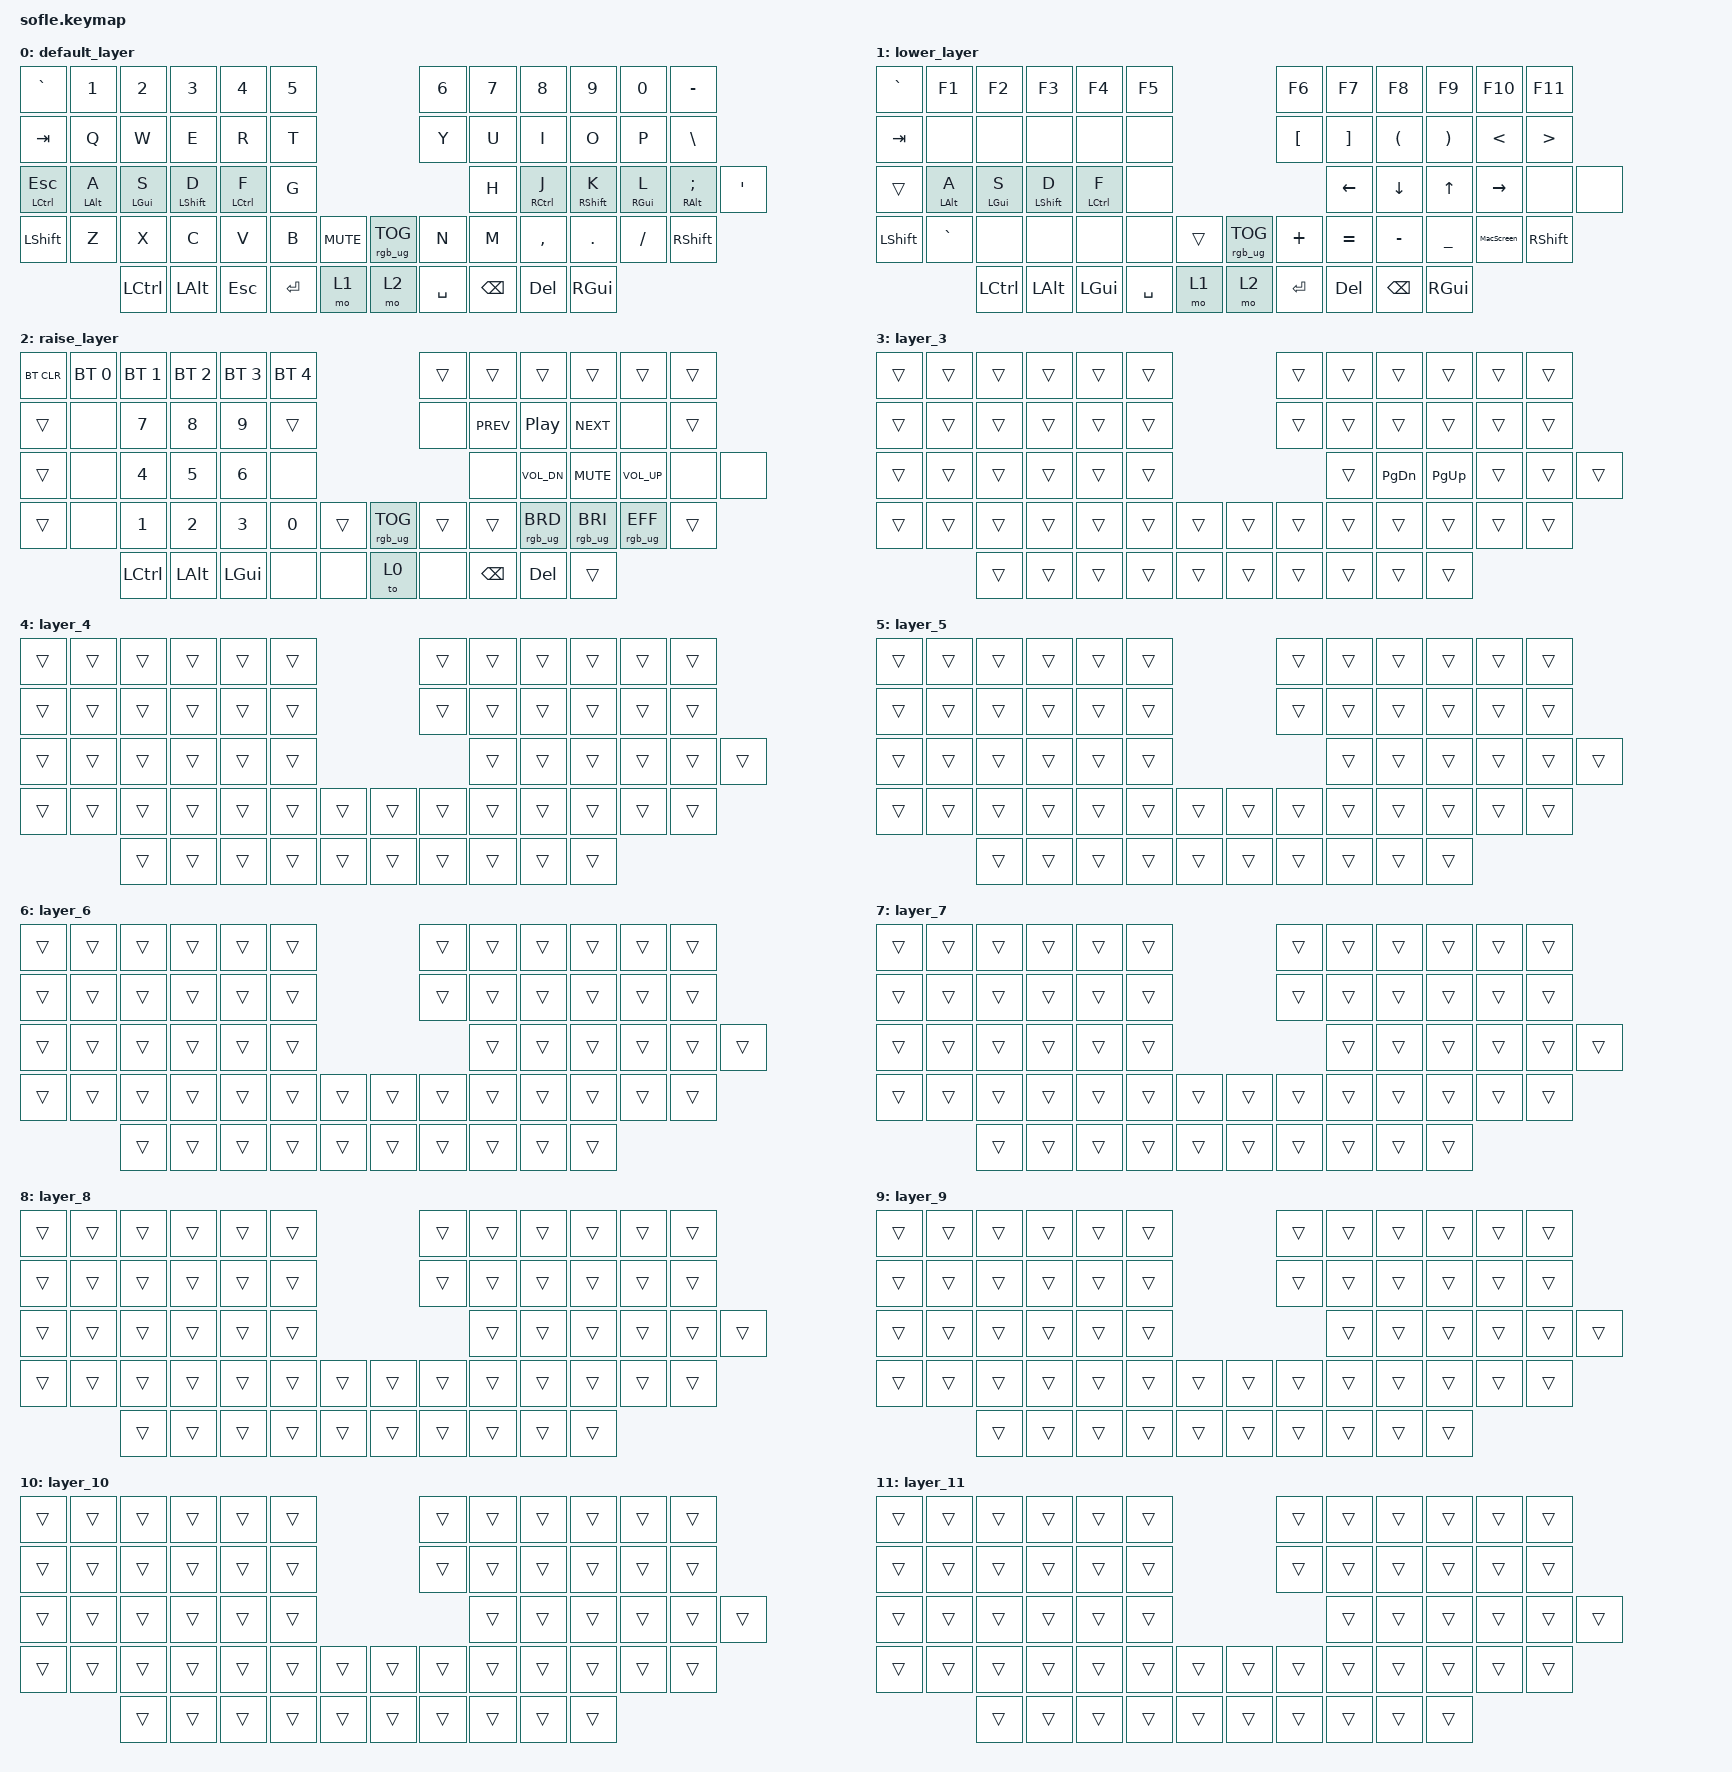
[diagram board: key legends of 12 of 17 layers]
/*
 * Copyright (c) 2020 The ZMK Contributors
 *
 * SPDX-License-Identifier: MIT
 */

#include <dt-bindings/led/led.h>
#include <behaviors.dtsi>
#include <dt-bindings/zmk/bt.h>
#include <dt-bindings/zmk/keys.h>
#include <dt-bindings/zmk/rgb.h>

&pinctrl {
    spi3_default: spi3_default {
        group1 { psels = <NRF_PSEL(SPIM_MOSI, 0, 8)>; };
    };

    spi3_sleep: spi3_sleep {
        group1 {
            psels = <NRF_PSEL(SPIM_MOSI, 0, 8)>;
            low-power-enable;
        };
    };
};

&spi3 {
    compatible = "nordic,nrf-spim";
    status = "okay";
    pinctrl-0 = <&spi3_default>;
    pinctrl-1 = <&spi3_sleep>;
    pinctrl-names = "default", "sleep";

    led_strip: ws2812@0 {
        compatible = "worldsemi,ws2812-spi";
        label = "WS2812";

        /* SPI */
        reg = <0>;
        spi-max-frequency = <4000000>;

        /* WS2812 */
        chain-length = <30>;
        spi-one-frame = <0x70>;
        spi-zero-frame = <0x40>;
        color-mapping = <LED_COLOR_ID_GREEN LED_COLOR_ID_RED LED_COLOR_ID_BLUE>;
    };
};

/ {
    chosen { zmk,underglow = &led_strip; };
};

/ {
    macros {
        MacScreen: MacScreen {
            compatible = "zmk,behavior-macro";
            #binding-cells = <0>;
            bindings = <&kp LSHFT &kp LCTRL &kp LGUI &kp KP_NUMBER_4>;
            label = "MACSCREEN";
        };
    };

    behaviors {
        // Caps key -> tap: ESC, hold: LCTRL
        escctrl: escape_control {
            compatible = "zmk,behavior-hold-tap";
            #binding-cells = <2>;
            tapping-term-ms = <200>;
            quick-tap-ms = <125>;
            flavor = "tap-preferred";
            bindings = <&kp>, <&kp>;
        };

        // Homerow mods - left hand
        // hold-trigger positions = all right hand keys so holds only fire toward opposite hand
        hml: homerow_mods_left {
            compatible = "zmk,behavior-hold-tap";
            #binding-cells = <2>;
            tapping-term-ms = <280>;
            quick-tap-ms = <175>;
            require-prior-idle-ms = <150>;
            flavor = "balanced";
            hold-trigger-key-positions = <
                6  7  8  9  10 11
                18 19 20 21 22 23
                30 31 32 33 34 35
                39 40 41 42 43 44 45 46 47 48 49 50 51
            >;
            hold-trigger-on-release;
            bindings = <&kp>, <&kp>;
        };

        // Homerow mods - right hand
        hmr: homerow_mods_right {
            compatible = "zmk,behavior-hold-tap";
            #binding-cells = <2>;
            tapping-term-ms = <280>;
            quick-tap-ms = <175>;
            require-prior-idle-ms = <150>;
            flavor = "balanced";
            hold-trigger-key-positions = <
                0  1  2  3  4  5
                12 13 14 15 16 17
                24 25 26 27 28 29
                36 37 38 39 40 41 42 43 44 45 46 47 48
            >;
            hold-trigger-on-release;
            bindings = <&kp>, <&kp>;
        };
    };

    keymap {
        compatible = "zmk,keymap";

        default_layer {
            // ---------------------------------------------------------------------------------------------------------------
            // |  `    |  1  |  2  |  3   |  4   |  5   |                         |  6   |  7    |  8    |  9   |   0   |  -   |
            // |  TAB  |  Q  |  W  |  E   |  R   |  T   |                         |  Y   |  U    |  I    |  O   |   P   |  \   |
            // |ESC/CTL|  A  |S/GUI|D/SFT |F/CTL |  G   |                         |  H   |J/CTL  |K/SFT  |L/GUI |;/RALT |  '   |
            // | SHIFT |  Z  |  X  |  C   |  V   |  B   |  MUTE  |      | RGB_TOG |  N   |  M    |  ,    |  .   |   /   | SHIFT|
            //               | CTRL| ALT  | GUI  | LOWER| SPACE  |      | ENTER   | RAISE| BSPC  | DEL   | GUI  |

            bindings = <
&kp GRAVE          &kp N1  &kp N2         &kp N3        &kp N4        &kp N5                                      &kp N6  &kp N7         &kp N8     &kp N9    &kp N0    &kp MINUS
&kp TAB            &kp Q   &kp W          &kp E         &kp R         &kp T                                       &kp Y   &kp U          &kp I      &kp O     &kp P     &kp BACKSLASH
&mt LCTL ESCAPE  &hml LALT A   &hml LGUI S    &hml LSHFT D  &hml LCTL F   &kp G                                    &kp H   &hmr RCTL J    &hmr RSHFT K  &hmr RGUI L  &hmr RALT SEMI  &kp SQT
&kp LSHFT          &kp Z   &kp X          &kp C         &kp V         &kp B   &kp C_MUTE      &rgb_ug RGB_TOG     &kp N   &kp M          &kp COMMA  &kp DOT   &kp FSLH  &kp RSHFT
                           &kp LCTRL      &kp LALT      &kp ESCAPE      &kp ENTER &mo 1         &mo 2               &kp SPACE  &kp BACKSPACE  &kp DEL    &kp RGUI
            >;

            sensor-bindings = <&inc_dec_kp C_VOL_UP C_VOL_DN &inc_dec_kp PG_UP PG_DN>;
        };

        lower_layer {
            // ------------------------------------------------------------------------------------------------------------
            // |       |  F1 |  F2 |  F3  |  F4  |  F5  |                   |  F6  |  F7   |  F8   |  F9  |  F10  |  =   |
            // |  TAB  |     |     |      |      |      |                   |      |  UP   |       |      |   [   |  ]   |
            // |       |     | PSCR|      |      |      |                   | LEFT | DOWN  | RIGHT |      |       |      |
            // |       |  `  |     |      |      |      |        |  RGB_TOG |      |       |       |      |MacScr |      |
            //               | CTRL| ALT  | GUI  |      | SPACE  |  ENTER  |      | BSPC  | DEL   |      |

            bindings = <
&kp GRAVE   &kp F1     &kp F2           &kp F3    &kp F4    &kp F5                                   &kp F6          &kp F7          &kp F8        &kp F9   &kp F10           &kp F11
&kp TAB     &none      &none            &none     &none     &none                                    &kp LEFT_BRACKET        &kp RIGHT_BRACKET        &kp LPAR        &kp RPAR   &kp LT  &kp GT
&trans      &hml LALT A   &hml LGUI S    &hml LSHFT D  &hml LCTL F     &none                         &kp LEFT_ARROW  &kp DOWN_ARROW  &kp UP_ARROW  &kp RIGHT_ARROW   &none             &none
&kp LSHFT   &kp GRAVE  &none            &none     &none     &none     &trans        &rgb_ug RGB_TOG    &kp PLUS       &kp EQUAL      &kp MINUS        &kp UNDERSCORE   &MacScreen        &kp RSHFT
                           &kp LCTRL    &kp LALT  &kp LGUI  &kp SPACE &mo 1         &mo 2              &kp ENTER       &kp DEL   &kp BACKSPACE    &kp RGUI
            >;

            sensor-bindings = <&inc_dec_kp C_VOL_UP C_VOL_DN &inc_dec_kp PG_UP PG_DN>;
        };
        
        
        raise_layer {
            // ------------------------------------------------------------------------------------------------------------
            // |BTCLR| BT1  | BT2  |  BT3  |  BT4  |  BT5 |                 |      |      |       |      |       |       |
            // |     | INS  | PSCR | GUI   |       |      |                 | PGUP |      |   ^   |      |       |       |
            // |     | ALT  | CTRL | SHIFT |       | CAPS |                 | PGDN |   <- |   v   |  ->  |  DEL  | BKSPC |
            // |     | UNDO | CUT  | COPY  | PASTE |      |      |   | RGB  |      |      |       |      |       |       |
            //              |      |       |       |      |      |   |      |      |      |       |      |

            bindings = <
&bt BT_CLR  &bt BT_SEL 0  &bt BT_SEL 1  &bt BT_SEL 2  &bt BT_SEL 3  &bt BT_SEL 4                                &trans  &trans         &trans           &trans           &trans           &trans
&trans      &none         &kp N7        &kp N8        &kp N9        &trans                                      &none   &kp C_PREV     &kp C_PLAY_PAUSE &kp C_NEXT       &none            &trans
&trans      &none         &kp N4        &kp N5        &kp N6        &none                                       &none   &kp C_VOL_DN   &kp C_MUTE       &kp C_VOL_UP     &none            &none
&trans      &none         &kp N1        &kp N2        &kp N3        &kp N0        &trans       &rgb_ug RGB_TOG  &trans  &trans         &rgb_ug RGB_BRD  &rgb_ug RGB_BRI  &rgb_ug RGB_EFF  &trans
                          &kp LCTRL     &kp LALT      &kp LGUI      &none         &none        &to 0            &none  &kp BACKSPACE  &kp DEL          &trans
            >;

            sensor-bindings = <&inc_dec_kp C_VOL_UP C_VOL_DN &inc_dec_kp PG_UP PG_DN &inc_dec_kp C_PREV C_NEXT>;
        };
        

        layer_3 {
            bindings = <
&trans  &trans  &trans  &trans  &trans  &trans                    &trans  &trans  &trans  &trans  &trans  &trans
&trans  &trans  &trans  &trans  &trans  &trans                    &trans  &trans  &trans  &trans  &trans  &trans
&trans  &trans  &trans  &trans  &trans  &trans                    &trans  &kp PG_DN  &kp PG_UP  &trans  &trans  &trans
&trans  &trans  &trans  &trans  &trans  &trans  &trans    &trans  &trans  &trans  &trans  &trans  &trans  &trans
                &trans  &trans  &trans  &trans  &trans    &trans  &trans  &trans  &trans  &trans
            >;
        };

        layer_4 {
            bindings = <
&trans  &trans  &trans  &trans  &trans  &trans                    &trans  &trans  &trans  &trans  &trans  &trans
&trans  &trans  &trans  &trans  &trans  &trans                    &trans  &trans  &trans  &trans  &trans  &trans
&trans  &trans  &trans  &trans  &trans  &trans                    &trans  &trans  &trans  &trans  &trans  &trans
&trans  &trans  &trans  &trans  &trans  &trans  &trans    &trans  &trans  &trans  &trans  &trans  &trans  &trans
                &trans  &trans  &trans  &trans  &trans    &trans  &trans  &trans  &trans  &trans
            >;
        };

        layer_5 {
            bindings = <
&trans  &trans  &trans  &trans  &trans  &trans                    &trans  &trans  &trans  &trans  &trans  &trans
&trans  &trans  &trans  &trans  &trans  &trans                    &trans  &trans  &trans  &trans  &trans  &trans
&trans  &trans  &trans  &trans  &trans  &trans                    &trans  &trans  &trans  &trans  &trans  &trans
&trans  &trans  &trans  &trans  &trans  &trans  &trans    &trans  &trans  &trans  &trans  &trans  &trans  &trans
                &trans  &trans  &trans  &trans  &trans    &trans  &trans  &trans  &trans  &trans
            >;
        };

        layer_6 {
            bindings = <
&trans  &trans  &trans  &trans  &trans  &trans                    &trans  &trans  &trans  &trans  &trans  &trans
&trans  &trans  &trans  &trans  &trans  &trans                    &trans  &trans  &trans  &trans  &trans  &trans
&trans  &trans  &trans  &trans  &trans  &trans                    &trans  &trans  &trans  &trans  &trans  &trans
&trans  &trans  &trans  &trans  &trans  &trans  &trans    &trans  &trans  &trans  &trans  &trans  &trans  &trans
                &trans  &trans  &trans  &trans  &trans    &trans  &trans  &trans  &trans  &trans
            >;
        };

        layer_7 {
            bindings = <
&trans  &trans  &trans  &trans  &trans  &trans                    &trans  &trans  &trans  &trans  &trans  &trans
&trans  &trans  &trans  &trans  &trans  &trans                    &trans  &trans  &trans  &trans  &trans  &trans
&trans  &trans  &trans  &trans  &trans  &trans                    &trans  &trans  &trans  &trans  &trans  &trans
&trans  &trans  &trans  &trans  &trans  &trans  &trans    &trans  &trans  &trans  &trans  &trans  &trans  &trans
                &trans  &trans  &trans  &trans  &trans    &trans  &trans  &trans  &trans  &trans
            >;
        };

        layer_8 {
            bindings = <
&trans  &trans  &trans  &trans  &trans  &trans                    &trans  &trans  &trans  &trans  &trans  &trans
&trans  &trans  &trans  &trans  &trans  &trans                    &trans  &trans  &trans  &trans  &trans  &trans
&trans  &trans  &trans  &trans  &trans  &trans                    &trans  &trans  &trans  &trans  &trans  &trans
&trans  &trans  &trans  &trans  &trans  &trans  &trans    &trans  &trans  &trans  &trans  &trans  &trans  &trans
                &trans  &trans  &trans  &trans  &trans    &trans  &trans  &trans  &trans  &trans
            >;
        };

        layer_9 {
            bindings = <
&trans  &trans  &trans  &trans  &trans  &trans                    &trans  &trans  &trans  &trans  &trans  &trans
&trans  &trans  &trans  &trans  &trans  &trans                    &trans  &trans  &trans  &trans  &trans  &trans
&trans  &trans  &trans  &trans  &trans  &trans                    &trans  &trans  &trans  &trans  &trans  &trans
&trans  &trans  &trans  &trans  &trans  &trans  &trans    &trans  &trans  &trans  &trans  &trans  &trans  &trans
                &trans  &trans  &trans  &trans  &trans    &trans  &trans  &trans  &trans  &trans
            >;
        };

        layer_10 {
            bindings = <
&trans  &trans  &trans  &trans  &trans  &trans                    &trans  &trans  &trans  &trans  &trans  &trans
&trans  &trans  &trans  &trans  &trans  &trans                    &trans  &trans  &trans  &trans  &trans  &trans
&trans  &trans  &trans  &trans  &trans  &trans                    &trans  &trans  &trans  &trans  &trans  &trans
&trans  &trans  &trans  &trans  &trans  &trans  &trans    &trans  &trans  &trans  &trans  &trans  &trans  &trans
                &trans  &trans  &trans  &trans  &trans    &trans  &trans  &trans  &trans  &trans
            >;
        };

        layer_11 {
            bindings = <
&trans  &trans  &trans  &trans  &trans  &trans                    &trans  &trans  &trans  &trans  &trans  &trans
&trans  &trans  &trans  &trans  &trans  &trans                    &trans  &trans  &trans  &trans  &trans  &trans
&trans  &trans  &trans  &trans  &trans  &trans                    &trans  &trans  &trans  &trans  &trans  &trans
&trans  &trans  &trans  &trans  &trans  &trans  &trans    &trans  &trans  &trans  &trans  &trans  &trans  &trans
                &trans  &trans  &trans  &trans  &trans    &trans  &trans  &trans  &trans  &trans
            >;
        };

        layer_12 {
            bindings = <
&trans  &trans  &trans  &trans  &trans  &trans                    &trans  &trans  &trans  &trans  &trans  &trans
&trans  &trans  &trans  &trans  &trans  &trans                    &trans  &trans  &trans  &trans  &trans  &trans
&trans  &trans  &trans  &trans  &trans  &trans                    &trans  &trans  &trans  &trans  &trans  &trans
&trans  &trans  &trans  &trans  &trans  &trans  &trans    &trans  &trans  &trans  &trans  &trans  &trans  &trans
                &trans  &trans  &trans  &trans  &trans    &trans  &trans  &trans  &trans  &trans
            >;
        };

        layer_13 {
            bindings = <
&trans  &trans  &trans  &trans  &trans  &trans                    &trans  &trans  &trans  &trans  &trans  &trans
&trans  &trans  &trans  &trans  &trans  &trans                    &trans  &trans  &trans  &trans  &trans  &trans
&trans  &trans  &trans  &trans  &trans  &trans                    &trans  &trans  &trans  &trans  &trans  &trans
&trans  &trans  &trans  &trans  &trans  &trans  &trans    &trans  &trans  &trans  &trans  &trans  &trans  &trans
                &trans  &trans  &trans  &trans  &trans    &trans  &trans  &trans  &trans  &trans
            >;
        };

        layer_14 {
            bindings = <
&trans  &trans  &trans  &trans  &trans  &trans                    &trans  &trans  &trans  &trans  &trans  &trans
&trans  &trans  &trans  &trans  &trans  &trans                    &trans  &trans  &trans  &trans  &trans  &trans
&trans  &trans  &trans  &trans  &trans  &trans                    &trans  &trans  &trans  &trans  &trans  &trans
&trans  &trans  &trans  &trans  &trans  &trans  &trans    &trans  &trans  &trans  &trans  &trans  &trans  &trans
                &trans  &trans  &trans  &trans  &trans    &trans  &trans  &trans  &trans  &trans
            >;
        };

        layer_15 {
            bindings = <
&trans  &trans  &trans  &trans  &trans  &trans                    &trans  &trans  &trans  &trans  &trans  &trans
&trans  &trans  &trans  &trans  &trans  &trans                    &trans  &trans  &trans  &trans  &trans  &trans
&trans  &trans  &trans  &trans  &trans  &trans                    &trans  &trans  &trans  &trans  &trans  &trans
&trans  &trans  &trans  &trans  &trans  &trans  &trans    &trans  &trans  &trans  &trans  &trans  &trans  &trans
                &trans  &trans  &trans  &trans  &trans    &trans  &trans  &trans  &trans  &trans
            >;
        };

        layer_16 {
            bindings = <
&trans  &trans  &trans  &trans  &trans  &trans                    &trans  &trans  &trans  &trans  &trans  &trans
&trans  &trans  &trans  &trans  &trans  &trans                    &trans  &trans  &trans  &trans  &trans  &trans
&trans  &trans  &trans  &trans  &trans  &trans                    &trans  &trans  &trans  &trans  &trans  &trans
&trans  &trans  &trans  &trans  &trans  &trans  &trans    &trans  &trans  &trans  &trans  &trans  &trans  &trans
                &trans  &trans  &trans  &trans  &trans    &trans  &trans  &trans  &trans  &trans
            >;
        };
    };
};
